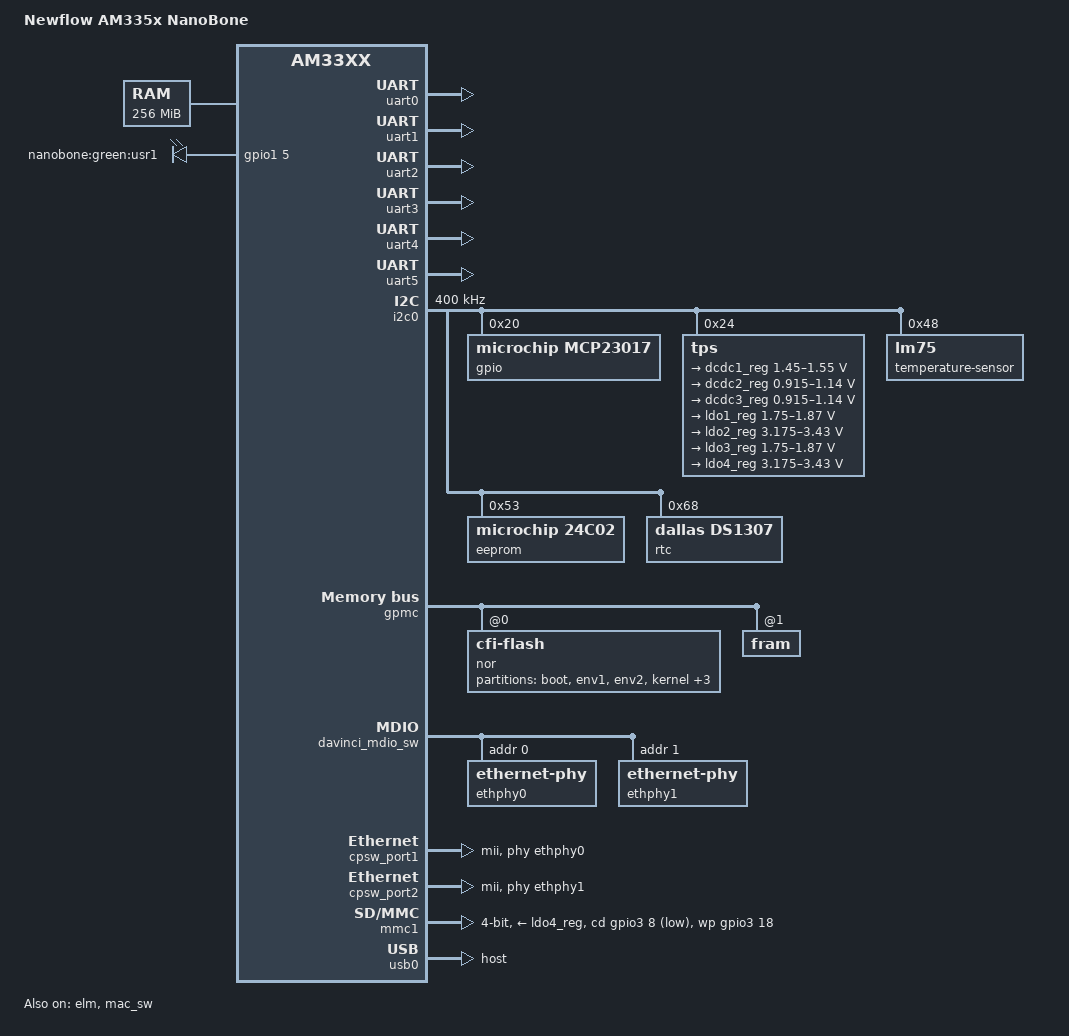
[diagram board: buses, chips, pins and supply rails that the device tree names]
/dts-v1/;
#include "am33xx.dtsi"
/ {
	model = "Newflow AM335x NanoBone";
	compatible = "ti,am33xx";
	cpus {
		cpu@0 {
			cpu0-supply = <&dcdc2_reg>;
		};
	};
	memory@80000000 {
		device_type = "memory";
		reg = <0x80000000 0x10000000>;  
	};
	leds {
		compatible = "gpio-leds";
		led0 {
			label = "nanobone:green:usr1";
			gpios = <&gpio1 5 0>;
			default-state = "off";
		};
	};
};
&am33xx_pinmux {
	pinctrl-names = "default";
	pinctrl-0 = <&misc_pins>;
	misc_pins: misc-pins {
		pinctrl-single,pins = <
			AM33XX_PADCONF(AM335X_PIN_SPI0_CS0, PIN_OUTPUT, MUX_MODE7)	 
		>;
	};
	gpmc_pins: gpmc-pins {
		pinctrl-single,pins = <
			AM33XX_PADCONF(AM335X_PIN_GPMC_AD0, PIN_INPUT_PULLUP, MUX_MODE0)
			AM33XX_PADCONF(AM335X_PIN_GPMC_AD1, PIN_INPUT_PULLUP, MUX_MODE0)
			AM33XX_PADCONF(AM335X_PIN_GPMC_AD2, PIN_INPUT_PULLUP, MUX_MODE0)
			AM33XX_PADCONF(AM335X_PIN_GPMC_AD3, PIN_INPUT_PULLUP, MUX_MODE0)
			AM33XX_PADCONF(AM335X_PIN_GPMC_AD4, PIN_INPUT_PULLUP, MUX_MODE0)
			AM33XX_PADCONF(AM335X_PIN_GPMC_AD5, PIN_INPUT_PULLUP, MUX_MODE0)
			AM33XX_PADCONF(AM335X_PIN_GPMC_AD6, PIN_INPUT_PULLUP, MUX_MODE0)
			AM33XX_PADCONF(AM335X_PIN_GPMC_AD7, PIN_INPUT_PULLUP, MUX_MODE0)
			AM33XX_PADCONF(AM335X_PIN_GPMC_AD8, PIN_INPUT_PULLUP, MUX_MODE0)
			AM33XX_PADCONF(AM335X_PIN_GPMC_AD9, PIN_INPUT_PULLUP, MUX_MODE0)
			AM33XX_PADCONF(AM335X_PIN_GPMC_AD10, PIN_INPUT_PULLUP, MUX_MODE0)
			AM33XX_PADCONF(AM335X_PIN_GPMC_AD11, PIN_INPUT_PULLUP, MUX_MODE0)
			AM33XX_PADCONF(AM335X_PIN_GPMC_AD12, PIN_INPUT_PULLUP, MUX_MODE0)
			AM33XX_PADCONF(AM335X_PIN_GPMC_AD13, PIN_INPUT_PULLUP, MUX_MODE0)
			AM33XX_PADCONF(AM335X_PIN_GPMC_AD14, PIN_INPUT_PULLUP, MUX_MODE0)
			AM33XX_PADCONF(AM335X_PIN_GPMC_AD15, PIN_INPUT_PULLUP, MUX_MODE0)
			AM33XX_PADCONF(AM335X_PIN_GPMC_WAIT0, PIN_INPUT_PULLUP, MUX_MODE0)
			AM33XX_PADCONF(AM335X_PIN_GPMC_CSN0, PIN_OUTPUT, MUX_MODE0)
			AM33XX_PADCONF(AM335X_PIN_GPMC_CSN1, PIN_OUTPUT, MUX_MODE0)
			AM33XX_PADCONF(AM335X_PIN_GPMC_CSN2, PIN_OUTPUT, MUX_MODE0)
			AM33XX_PADCONF(AM335X_PIN_GPMC_CSN3, PIN_OUTPUT, MUX_MODE0)
			AM33XX_PADCONF(AM335X_PIN_GPMC_ADVN_ALE, PIN_OUTPUT, MUX_MODE0)
			AM33XX_PADCONF(AM335X_PIN_GPMC_OEN_REN, PIN_OUTPUT, MUX_MODE0)
			AM33XX_PADCONF(AM335X_PIN_GPMC_WEN, PIN_OUTPUT, MUX_MODE0)
			AM33XX_PADCONF(AM335X_PIN_GPMC_BEN0_CLE, PIN_OUTPUT, MUX_MODE0)
			AM33XX_PADCONF(AM335X_PIN_LCD_DATA1, PIN_OUTPUT, MUX_MODE1)		 
			AM33XX_PADCONF(AM335X_PIN_LCD_DATA2, PIN_OUTPUT, MUX_MODE1)		 
			AM33XX_PADCONF(AM335X_PIN_LCD_DATA3, PIN_OUTPUT, MUX_MODE1)		 
			AM33XX_PADCONF(AM335X_PIN_LCD_DATA4, PIN_OUTPUT, MUX_MODE1)		 
			AM33XX_PADCONF(AM335X_PIN_LCD_DATA5, PIN_OUTPUT, MUX_MODE1)		 
			AM33XX_PADCONF(AM335X_PIN_LCD_DATA6, PIN_OUTPUT, MUX_MODE1)		 
			AM33XX_PADCONF(AM335X_PIN_LCD_DATA7, PIN_OUTPUT, MUX_MODE1)		 
			AM33XX_PADCONF(AM335X_PIN_LCD_VSYNC, PIN_OUTPUT, MUX_MODE1)		 
			AM33XX_PADCONF(AM335X_PIN_LCD_HSYNC, PIN_OUTPUT, MUX_MODE1)		 
			AM33XX_PADCONF(AM335X_PIN_LCD_PCLK, PIN_OUTPUT, MUX_MODE1)		 
		>;
	};
	i2c0_pins: i2c0-pins {
		pinctrl-single,pins = <
			AM33XX_PADCONF(AM335X_PIN_I2C0_SDA, PIN_INPUT_PULLDOWN, MUX_MODE0)
			AM33XX_PADCONF(AM335X_PIN_I2C0_SCL, PIN_INPUT_PULLDOWN, MUX_MODE0)
		>;
	};
	uart0_pins: uart0-pins {
		pinctrl-single,pins = <
			AM33XX_PADCONF(AM335X_PIN_UART0_RXD, PIN_INPUT_PULLUP, MUX_MODE0)
			AM33XX_PADCONF(AM335X_PIN_UART0_TXD, PIN_OUTPUT, MUX_MODE0)
		>;
	};
	uart1_pins: uart1-pins {
		pinctrl-single,pins = <
			AM33XX_PADCONF(AM335X_PIN_UART1_CTSN, PIN_OUTPUT, MUX_MODE7)
			AM33XX_PADCONF(AM335X_PIN_UART1_RTSN, PIN_OUTPUT, MUX_MODE7)
			AM33XX_PADCONF(AM335X_PIN_UART1_RXD, PIN_INPUT_PULLUP, MUX_MODE0)
			AM33XX_PADCONF(AM335X_PIN_UART1_TXD, PIN_OUTPUT, MUX_MODE0)
		>;
	};
	uart2_pins: uart2-pins {
		pinctrl-single,pins = <
			AM33XX_PADCONF(AM335X_PIN_LCD_DATA8, PIN_INPUT_PULLUP, MUX_MODE7)	 
			AM33XX_PADCONF(AM335X_PIN_LCD_DATA9, PIN_OUTPUT, MUX_MODE7)		 
			AM33XX_PADCONF(AM335X_PIN_SPI0_SCLK, PIN_INPUT, MUX_MODE1)		 
			AM33XX_PADCONF(AM335X_PIN_SPI0_D0, PIN_OUTPUT, MUX_MODE1)		 
		>;
	};
	uart3_pins: uart3-pins {
		pinctrl-single,pins = <
			AM33XX_PADCONF(AM335X_PIN_LCD_DATA10, PIN_INPUT_PULLUP, MUX_MODE7)	 
			AM33XX_PADCONF(AM335X_PIN_LCD_DATA11, PIN_OUTPUT, MUX_MODE7)		 
			AM33XX_PADCONF(AM335X_PIN_SPI0_CS1, PIN_INPUT, MUX_MODE1)		 
			AM33XX_PADCONF(AM335X_PIN_ECAP0_IN_PWM0_OUT, PIN_OUTPUT, MUX_MODE1)		 
		>;
	};
	uart4_pins: uart4-pins {
		pinctrl-single,pins = <
			AM33XX_PADCONF(AM335X_PIN_LCD_DATA12, PIN_INPUT_PULLUP, MUX_MODE7)	 
			AM33XX_PADCONF(AM335X_PIN_LCD_DATA13, PIN_OUTPUT, MUX_MODE7)		 
			AM33XX_PADCONF(AM335X_PIN_UART0_CTSN, PIN_INPUT, MUX_MODE1)		 
			AM33XX_PADCONF(AM335X_PIN_UART0_RTSN, PIN_OUTPUT, MUX_MODE1)		 
		>;
	};
	uart5_pins: uart5-pins {
		pinctrl-single,pins = <
			AM33XX_PADCONF(AM335X_PIN_LCD_DATA14, PIN_INPUT, MUX_MODE4)		 
			AM33XX_PADCONF(AM335X_PIN_RMII1_REF_CLK, PIN_OUTPUT, MUX_MODE3)		 
		>;
	};
	mmc1_pins: mmc1-pins {
		pinctrl-single,pins = <
			AM33XX_PADCONF(AM335X_PIN_MMC0_DAT3, PIN_INPUT_PULLUP, MUX_MODE0)
			AM33XX_PADCONF(AM335X_PIN_MMC0_DAT2, PIN_INPUT_PULLUP, MUX_MODE0)
			AM33XX_PADCONF(AM335X_PIN_MMC0_DAT1, PIN_INPUT_PULLUP, MUX_MODE0)
			AM33XX_PADCONF(AM335X_PIN_MMC0_DAT0, PIN_INPUT_PULLUP, MUX_MODE0)
			AM33XX_PADCONF(AM335X_PIN_MMC0_CLK, PIN_INPUT_PULLUP, MUX_MODE0)	 
			AM33XX_PADCONF(AM335X_PIN_MMC0_CMD, PIN_INPUT_PULLUP, MUX_MODE0)	 
			AM33XX_PADCONF(AM335X_PIN_EMU1, PIN_INPUT_PULLUP, MUX_MODE7)	 
			AM33XX_PADCONF(AM335X_PIN_MCASP0_ACLKR, PIN_INPUT_PULLUP, MUX_MODE7)	 
		>;
	};
};
&uart0 {
	pinctrl-names = "default";
	pinctrl-0 = <&uart0_pins>;
	status = "okay";
};
&uart1 {
	pinctrl-names = "default";
	pinctrl-0 = <&uart1_pins>;
	status = "okay";
	rts-gpio = <&gpio0 13 GPIO_ACTIVE_HIGH>;
	rs485-rts-active-high;
	rs485-rx-during-tx;
	rs485-rts-delay = <1 1>;
	linux,rs485-enabled-at-boot-time;
};
&uart2 {
	pinctrl-names = "default";
	pinctrl-0 = <&uart2_pins>;
	status = "okay";
	rts-gpio = <&gpio2 15 GPIO_ACTIVE_HIGH>;
	rs485-rts-active-high;
	rs485-rts-delay = <1 1>;
	linux,rs485-enabled-at-boot-time;
};
&uart3 {
	pinctrl-names = "default";
	pinctrl-0 = <&uart3_pins>;
	rts-gpio = <&gpio2 17 GPIO_ACTIVE_HIGH>;
	rs485-rts-active-high;
	rs485-rx-during-tx;
	rs485-rts-delay = <1 1>;
	linux,rs485-enabled-at-boot-time;
	status = "okay";
};
&uart4 {
	pinctrl-names = "default";
	pinctrl-0 = <&uart4_pins>;
	rts-gpio = <&gpio0 9 GPIO_ACTIVE_HIGH>;
	rs485-rts-active-high;
	rs485-rx-during-tx;
	rs485-rts-delay = <1 1>;
	linux,rs485-enabled-at-boot-time;
	status = "okay";
};
&uart5 {
	pinctrl-names = "default";
	pinctrl-0 = <&uart5_pins>;
	status = "okay";
};
&i2c0 {
	status = "okay";
	pinctrl-names = "default";
	clock-frequency = <400000>;
	pinctrl-names = "default";
	pinctrl-0 = <&i2c0_pins>;
	gpio@20 {
		compatible = "microchip,mcp23017";
		gpio-controller;
		#gpio-cells = <2>;
		reg = <0x20>;
	};
	tps: tps@24 {
		reg = <0x24>;
	};
	temperature-sensor@48 {
		compatible = "lm75";
		reg = <0x48>;
	};
	eeprom@53 {
		compatible = "microchip,24c02", "atmel,24c02";
		reg = <0x53>;
		pagesize = <8>;
	};
	rtc@68 {
		compatible = "dallas,ds1307";
		reg = <0x68>;
	};
};
&elm {
	status = "okay";
};
&gpmc {
	compatible = "ti,am3352-gpmc";
	status = "okay";
	gpmc,num-waitpins = <2>;
	pinctrl-names = "default";
	pinctrl-0 = <&gpmc_pins>;
	#address-cells = <2>;
	#size-cells = <1>;
	ranges = <0 0 0x08000000 0x08000000>,	 
		 <1 0 0x1c000000 0x01000000>;	 
	nor@0,0 {
		reg = <0 0x00000000 0x08000000>;
		compatible = "cfi-flash";
		linux,mtd-name = "spansion,s29gl010p11t";
		bank-width = <2>;
		gpmc,mux-add-data = <2>;
		gpmc,sync-clk-ps = <0>;
		gpmc,cs-on-ns = <0>;
		gpmc,cs-rd-off-ns = <160>;
		gpmc,cs-wr-off-ns = <160>;
		gpmc,adv-on-ns = <10>;
		gpmc,adv-rd-off-ns = <30>;
		gpmc,adv-wr-off-ns = <30>;
		gpmc,oe-on-ns = <40>;
		gpmc,oe-off-ns = <160>;
		gpmc,we-on-ns = <40>;
		gpmc,we-off-ns = <160>;
		gpmc,rd-cycle-ns = <160>;
		gpmc,wr-cycle-ns = <160>;
		gpmc,access-ns = <150>;
		gpmc,page-burst-access-ns = <10>;
		gpmc,cycle2cycle-samecsen;
		gpmc,cycle2cycle-delay-ns = <20>;
		gpmc,wr-data-mux-bus-ns = <70>;
		gpmc,wr-access-ns = <80>;
		#address-cells = <1>;
		#size-cells = <1>;
		partition@0 {
			label = "boot";
			reg = <0x00000000 0x000c0000>;  
		};
		partition@1 {
			label = "env1";
			reg = <0x000c0000 0x00020000>;  
		};
		partition@2 {
			label = "env2";
			reg = <0x000e0000 0x00020000>;  
		};
		partition@3 {
			label = "kernel";
			reg = <0x00100000 0x00400000>;  
		};
		partition@4 {
			label = "rootfs";
			reg = <0x00500000 0x01b00000>;  
		};
		partition@5 {
			label = "user";
			reg = <0x02000000 0x02000000>;  
		};
		partition@6 {
			label = "data";
			reg = <0x04000000 0x04000000>;  
		};
	};
	fram@1,0 {
		reg = <1 0x00000000 0x01000000>;
		bank-width = <2>;
		gpmc,mux-add-data = <2>;
		gpmc,sync-clk-ps = <0>;
		gpmc,cs-on-ns = <0>;
		gpmc,cs-rd-off-ns = <160>;
		gpmc,cs-wr-off-ns = <160>;
		gpmc,adv-on-ns = <10>;
		gpmc,adv-rd-off-ns = <20>;
		gpmc,adv-wr-off-ns = <20>;
		gpmc,oe-on-ns = <30>;
		gpmc,oe-off-ns = <150>;
		gpmc,we-on-ns = <30>;
		gpmc,we-off-ns = <150>;
		gpmc,rd-cycle-ns = <160>;
		gpmc,wr-cycle-ns = <160>;
		gpmc,access-ns = <130>;
		gpmc,page-burst-access-ns = <10>;
		gpmc,cycle2cycle-samecsen;
		gpmc,cycle2cycle-diffcsen;
		gpmc,cycle2cycle-delay-ns = <10>;
		gpmc,wr-data-mux-bus-ns = <30>;
		gpmc,wr-access-ns = <0>;
	};
};
&mac_sw {
	status = "okay";
};
&davinci_mdio_sw {
	status = "okay";
	ethphy0: ethernet-phy@0 {
		reg = <0>;
	};
	ethphy1: ethernet-phy@1 {
		reg = <1>;
	};
};
&cpsw_port1 {
	phy-handle = <&ethphy0>;
	phy-mode = "mii";
	ti,dual-emac-pvid = <1>;
};
&cpsw_port2 {
	phy-handle = <&ethphy1>;
	phy-mode = "mii";
	ti,dual-emac-pvid = <2>;
};
&mmc1 {
	status = "okay";
	vmmc-supply = <&ldo4_reg>;
	pinctrl-names = "default";
	pinctrl-0 = <&mmc1_pins>;
	bus-width = <4>;
	cd-debounce-delay-ms = <5>;
	cd-gpios = <&gpio3 8 GPIO_ACTIVE_LOW>;
	wp-gpios = <&gpio3 18 GPIO_ACTIVE_HIGH>;
};
&usb0 {
	dr_mode = "host";
};
#include "../../tps65217.dtsi"
&tps {
	regulators {
		dcdc1_reg: regulator@0 {
			regulator-min-microvolt = <1450000>;
			regulator-max-microvolt = <1550000>;
			regulator-boot-on;
			regulator-always-on;
		};
		dcdc2_reg: regulator@1 {
			regulator-name = "vdd_mpu";
			regulator-min-microvolt = <915000>;
			regulator-max-microvolt = <1140000>;
			regulator-boot-on;
			regulator-always-on;
		};
		dcdc3_reg: regulator@2 {
			regulator-name = "vdd_core";
			regulator-min-microvolt = <915000>;
			regulator-max-microvolt = <1140000>;
			regulator-boot-on;
			regulator-always-on;
		};
		ldo1_reg: regulator@3 {
			regulator-min-microvolt = <1750000>;
			regulator-max-microvolt = <1870000>;
			regulator-boot-on;
			regulator-always-on;
		};
		ldo2_reg: regulator@4 {
			regulator-min-microvolt = <3175000>;
			regulator-max-microvolt = <3430000>;
			regulator-boot-on;
			regulator-always-on;
		};
		ldo3_reg: regulator@5 {
			regulator-min-microvolt = <1750000>;
			regulator-max-microvolt = <1870000>;
			regulator-boot-on;
			regulator-always-on;
		};
		ldo4_reg: regulator@6 {
			regulator-min-microvolt = <3175000>;
			regulator-max-microvolt = <3430000>;
			regulator-boot-on;
			regulator-always-on;
		};
	};
};
